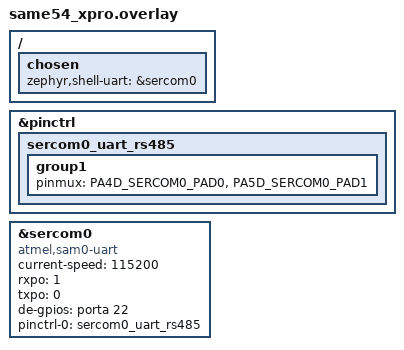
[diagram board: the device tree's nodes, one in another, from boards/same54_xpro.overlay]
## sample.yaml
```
sample:
  name: UART RS485 Echo Bot
  description: RS485 echo bot sample using UART with transceiver control
tests:
  sample.drivers.uart.rs485:
    platform_allow:
      - same54_xpro
    integration_platforms:
      - same54_xpro
    tags:
      - serial
      - uart
      - rs485
    filter: CONFIG_SERIAL and
            CONFIG_UART_INTERRUPT_DRIVEN and
            CONFIG_GPIO and
            dt_chosen_enabled("zephyr,shell-uart")
    harness: keyboard
```

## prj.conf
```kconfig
CONFIG_SERIAL=y
CONFIG_UART_INTERRUPT_DRIVEN=y

# Enable RS485 support
CONFIG_UART_USE_RUNTIME_CONFIGURE=y

# Enable GPIO for DE/RE control
CONFIG_GPIO=y
```

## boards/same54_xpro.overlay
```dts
/*
 * Copyright (c) 2025 Altronix
 * SPDX-License-Identifier: Apache-2.0
 */

/*
 * RS485 Echo Bot configuration for SAME54 Xplained Pro
 * Using SERCOM0 with:
 *   - TX on PA04 (SERCOM0 PAD0)
 *   - RX on PA05 (SERCOM0 PAD1)
 *   - DE/RE on PA22 (Driver Enable and Receiver Enable tied together)
 */

#include <dt-bindings/pinctrl/same54p-pinctrl.h>

/* Add SERCOM0 pinctrl configuration */
&pinctrl {
	sercom0_uart_rs485: sercom0_uart_rs485 {
		group1 {
			pinmux = <PA4D_SERCOM0_PAD0>,  /* TX */
				 <PA5D_SERCOM0_PAD1>;  /* RX */
		};
	};
};

/* Configure SERCOM0 as UART with RS485 support */
&sercom0 {
	status = "okay";
	compatible = "atmel,sam0-uart";
	current-speed = <115200>;
	rxpo = <1>;  /* RX on PAD1 */
	txpo = <0>;  /* TX on PAD0 */

	/*
	 * RS485 transceiver control
	 *
	 * Option 1: DE and RE tied together (RECOMMENDED - most common)
	 * ---------------------------------------------------------------
	 * If your RS485 transceiver has DE and RE pins connected together,
	 * only specify de-gpios:
	 *
	 *   de-gpios = <&porta 22 GPIO_ACTIVE_HIGH>;
	 *
	 * The driver will:
	 *   - Set GPIO HIGH during transmit (enables driver)
	 *   - Set GPIO LOW during receive (enables receiver)
	 *
	 * Option 2: Separate DE and RE control
	 * -------------------------------------
	 * If your transceiver has separate DE and RE pins, specify both:
	 *
	 *   de-gpios = <&porta 22 GPIO_ACTIVE_HIGH>;
	 *   re-gpios = <&porta 23 GPIO_ACTIVE_LOW>;
	 *
	 * Note: RE is typically active-low (inverted), so when the driver
	 * "enables RX", it sets the GPIO to 1, which pulls RE low.
	 */
	de-gpios = <&porta 22 GPIO_ACTIVE_HIGH>;

	pinctrl-0 = <&sercom0_uart_rs485>;
	pinctrl-names = "default";
};

/* Override the chosen UART for this sample */
/ {
	chosen {
		zephyr,shell-uart = &sercom0;
	};
};
```

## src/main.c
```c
/*
 * Copyright (c) 2022 Libre Solar Technologies GmbH
 *
 * SPDX-License-Identifier: Apache-2.0
 */

#include <zephyr/kernel.h>
#include <zephyr/device.h>
#include <zephyr/drivers/uart.h>

#include <string.h>

/* change this to any other UART peripheral if desired */
#define UART_DEVICE_NODE DT_CHOSEN(zephyr_shell_uart)

#define MSG_SIZE 32

/* queue to store up to 10 messages (aligned to 4-byte boundary) */
K_MSGQ_DEFINE(uart_msgq, MSG_SIZE, 10, 4);

static const struct device *const uart_dev = DEVICE_DT_GET(UART_DEVICE_NODE);

/* receive buffer used in UART ISR callback */
static char rx_buf[MSG_SIZE];
static int rx_buf_pos;

/*
 * Read characters from UART until line end is detected. Afterwards push the
 * data to the message queue.
 */
void serial_cb(const struct device *dev, void *user_data)
{
	uint8_t c;

	if (!uart_irq_update(uart_dev)) {
		return;
	}

	if (!uart_irq_rx_ready(uart_dev)) {
		return;
	}

	/* read until FIFO empty */
	while (uart_fifo_read(uart_dev, &c, 1) == 1) {
		if ((c == '\n' || c == '\r') && rx_buf_pos > 0) {
			/* terminate string */
			rx_buf[rx_buf_pos] = '\0';

			/* if queue is full, message is silently dropped */
			k_msgq_put(&uart_msgq, &rx_buf, K_NO_WAIT);

			/* reset the buffer (it was copied to the msgq) */
			rx_buf_pos = 0;
		} else if (rx_buf_pos < (sizeof(rx_buf) - 1)) {
			rx_buf[rx_buf_pos++] = c;
		}
		/* else: characters beyond buffer size are dropped */
	}
}

/*
 * Print a null-terminated string character by character to the UART interface
 */
void print_uart(char *buf)
{
	int msg_len = strlen(buf);

	for (int i = 0; i < msg_len; i++) {
		uart_poll_out(uart_dev, buf[i]);
	}
}

int main(void)
{
	char tx_buf[MSG_SIZE];

	if (!device_is_ready(uart_dev)) {
		printk("UART device not found!");
		return 0;
	}

	/* Configure UART for RS485 mode */
	struct uart_config uart_cfg;
	int ret = uart_config_get(uart_dev, &uart_cfg);

	if (ret == 0) {
		uart_cfg.flow_ctrl = UART_CFG_FLOW_CTRL_RS485;
		ret = uart_configure(uart_dev, &uart_cfg);
		if (ret < 0) {
			printk("Failed to configure RS485 mode: %d\n", ret);
			return 0;
		}
		printk("RS485 mode enabled\n");
	} else {
		printk("Failed to get UART config: %d\n", ret);
	}

	/* configure interrupt and callback to receive data */
	ret = uart_irq_callback_user_data_set(uart_dev, serial_cb, NULL);

	if (ret < 0) {
		if (ret == -ENOTSUP) {
			printk("Interrupt-driven UART API support not enabled\n");
		} else if (ret == -ENOSYS) {
			printk("UART device does not support interrupt-driven API\n");
		} else {
			printk("Error setting UART callback: %d\n", ret);
		}
		return 0;
	}
	uart_irq_rx_enable(uart_dev);

	print_uart("Hello! I'm your echo bot.\r\n");
	print_uart("Tell me something and press enter:\r\n");

	/* indefinitely wait for input from the user */
	while (k_msgq_get(&uart_msgq, &tx_buf, K_FOREVER) == 0) {
		print_uart("Echo: ");
		print_uart(tx_buf);
		print_uart("\r\n");
	}
	return 0;
}
```
